# AC33Mx128 register map
Vendor: ABOV Semiconductor Co., Ltd.; File version: 0.6
ARM 32-bit Cortex-M3 Microcontroller based device.
CPU: CM3 r1p0, little endian, no MPU, no FPU, 3 interrupt priority bits
Registers are 32-bit, read-write, reset 0x0 unless marked. A register's access mark holds for its fields unless they carry their own. Offsets are from the block's base; lines under a group give offsets from that group; [hi:lo] are bit positions; {n}, {i} and the like mark numbered series; 'fields as' and 'values as' point back to an identical list; <NAME> marks a mode.

## Memory map
0x40000000 SCU size 0x100 — SYSTEM CONTROL UNIT
0x40000100 FM size 0x100 — FLASH MEMORY CONTROLLER
0x40000200 WDT size 0x100 — WATCH-DOG TIMER
0x40000400 DC0 size 0x10 — DIRECT MEMORY ACCESS CONTROLLER
{0x40000400+0x10*n} DC{n} size 0x10 (n=1..14)
0x40001000 PCA size 0x100 — PORT CONTROL UNIT
0x40001100 PCB size 0x100
0x40001200 PCC size 0x100
0x40001300 PCD size 0x100
0x40001FF0 PORTEN size 0x10 — Port Access Eable
0x40002000 PA size 0x100 — GENERAL PURPOSE I/O
0x40002100 PB size 0x100
0x40002200 PC size 0x100
0x40002300 PD size 0x100
0x40003000 T0 size 0x20 — 16-BIT TIMER
0x40003020 T1 size 0x20
0x40003040 T2 size 0x20
0x40003060 T3 size 0x20
0x40003100 T8 size 0x20
0x40003120 T9 size 0x20
0x40003140 TGECR size 0x10 — Timer Group Encoder Control Register
0x40004000 MP0 size 0x1000 — MOTOR PULSE-WIDTH-MODULATOR
0x40005000 MP1 size 0x1000
0x40008000 U0 size 0x100 — UNIVERSAL ASYNCHRONOUS RECEIVER/TRANSMITTER
0x40008100 U1 size 0x100
0x40008200 U2 size 0x100
0x40008300 U3 size 0x100
0x40009000 SP0 size 0x100 — SERIAL PERIPHERAL INTERFACE
0x40009100 SP1 size 0x100
0x4000A000 IC0 size 0x100 — IIC Interface
0x4000A100 IC1 size 0x100
0x4000B000 AD0 size 0x100 — 12-BIT A/D CONVERTER
0x4000B100 AD1 size 0x100
0x4000B200 AD2 size 0x100
0x4000B300 AFE size 0x100 — ANALOG FRONT END

## Interrupts
0 LVDDETECT (SCU)
1 SCLKFAIL (SCU)
2 XOSCFAIL (SCU)
3 WDT
5 TIMER0 (T0)
6 TIMER1 (T1)
7 TIMER2 (T2)
8 TIMER3 (T3)
13 TIMER8 (T8)
14 TIMER9 (T9)
16 GPIOAE (PCA)
17 GPIOAO (PCA)
18 GPIOBE (PCB)
19 GPIOBO (PCB)
20 GPIOCE (PCC)
21 GPIOCO (PCC)
22 GPIODE (PCD)
23 GPIODO (PCD)
24 MPWM0 (MP0)
25 MPWM0PROT (MP0)
26 MPWM0OVV (MP0)
27 MPWM1 (MP1)
28 MPWM1PROT (MP1)
29 MPWM1OVV (MP1)
32 SPI0 (SP0)
33 SPI1 (SP1)
36 IIC0 (IC0)
37 IIC1 (IC1)
38 UART0 (U0)
39 UART1 (U1)
40 UART2 (U2)
41 UART3 (U3)
43 ADC0 (AD0)
44 ADC1 (AD1)
45 ADC2 (AD2)
46 COMP0 (AFE)
47 COMP1 (AFE)
48 COMP2 (AFE)
49 COMP3 (AFE)

## FM — FLASH MEMORY CONTROLLER
Base 0x40000100
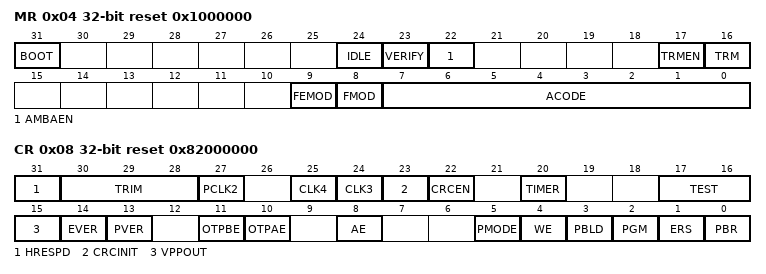
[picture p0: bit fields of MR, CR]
0x04 MR reset 0x1000000 — Flash Memory Mode Register
  [31] BOOT ro — Boot Mode enable status
  [24] IDLE ro — Idle mode enable status
  [23] VERIFY ro — Flash verify Mode enable status
  [22] AMBAEN — AMBA mode enable
  [17] TRMEN ro — Trim Mode entry status
  [16] TRM ro — Trim Mode status
  [9] FEMOD ro — Flash Mode entry status
  [8] FMOD ro — Flash Mode status
  [7:0] ACODE — Flash Mode/Trim Mode
0x08 CR reset 0x82000000 — Flash Memory Control Register
  [31] HRESPD ro
  [30:28] TRIM ro
  [27] PCLK2 ro — PCLK=HCLK*1/2
  [25] CLK4 ro — flash access CLK
  [24] CLK3 ro — flash access CLK
  [23] CRCINIT ro
  [22] CRCEN — CRC16 Enable
  [20] TIMER ro — program timer enable
  [17:16] TEST ro
  [15] VPPOUT ro — Charge pump Vpp Output
  [14] EVER ro — Erase verify Mode
  [13] PVER ro — Program verify mode
  [11] OTPBE ro — OTP area B enable
  [10] OTPAE ro — OTP area A enable
  [8] AE ro — All Erase
  [5] PMODE — Pmode Enable
  [4] WE — write Enable
  [3] PBLD — page buffer load
  [2] PGM
  [1] ERS — program mode/erase mode Enable
  [0] PBR — page buffer reset
0x0C AR — Flash Memory Address Register
  [14:0] FADDR — 32K words address
0x10 DR — Flash Memory Data Register
  [31:0] FDATA — Flash PGM data
0x14 TMR reset 0xBB — Flash Memory Timer Register
  [8:0] TMR — Erase/PGM timer
0x18 DRTY — Flash Memory Dirty bit Register
  [31:0] FDRTY — Write any value,cache line fill falg will be cleared
0x1C TICK — Flash Memory Tick Timer register
  [17:0] FTICK — TICK
0x20 CRC — Flash Memory CRC value register
  [15:0] CRC — CRC16 Value
0x74 BOOTCR reset 0x1 — Boot ROM Remap Clear Register
  [0] BOOTROM — Boot mode

## Licence text in the file
THIS SOFTWARE IS PROVIDED "AS IS". NO WARRANTIES, WHETHER EXPRESS, IMPLIED. OR STATUTORY, INCLUDING, BUT NOT LIMITED TO, IMPLIED WARRANTIES OF. MERCHANTABILITY AND FITNESS FOR A PARTICULAR PURPOSE APPLY TO THIS SOFTWARE. ARM SHALL NOT, IN ANY CIRCUMSTANCES, BE LIABLE FOR SPECIAL, INCIDENTAL, OR. CONSEQUENTIAL DAMAGES, FOR ANY REASON WHATSOEVER.
